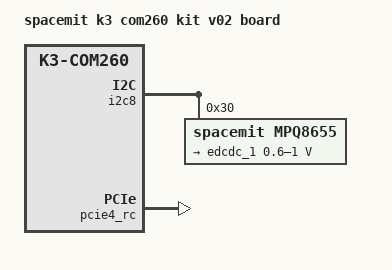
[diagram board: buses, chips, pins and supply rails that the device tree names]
// SPDX-License-Identifier: GPL-2.0
/*
 * k3 com260 kit v02 board device tree (U-Boot).
 *
 * Copyright (C) 2025 SPACEMIT Micro Limited
 */

#include "k3_com260.dtsi"

/ {
	model = "spacemit k3 com260 kit v02 board";
};

&i2c8 {
	mpq8655: mpq8655@30 {
		compatible = "spacemit,mpq8655";
		reg = <0x30>;
		bus = <8>;
		u-boot,dm-spl;

		regulators {
			edcdc_1: EDCDC_REG1 {
				regulator-name = "edcdc1";
				regulator-min-microvolt = <600000>;
				regulator-max-microvolt = <1000000>;
				regulator-init-microvolt = <880000>;
				regulator-always-on;
				regulator-boot-on;
				u-boot,dm-spl;
			};
		};
	};
};

&pcie4_rc {
	status = "okay";
};
